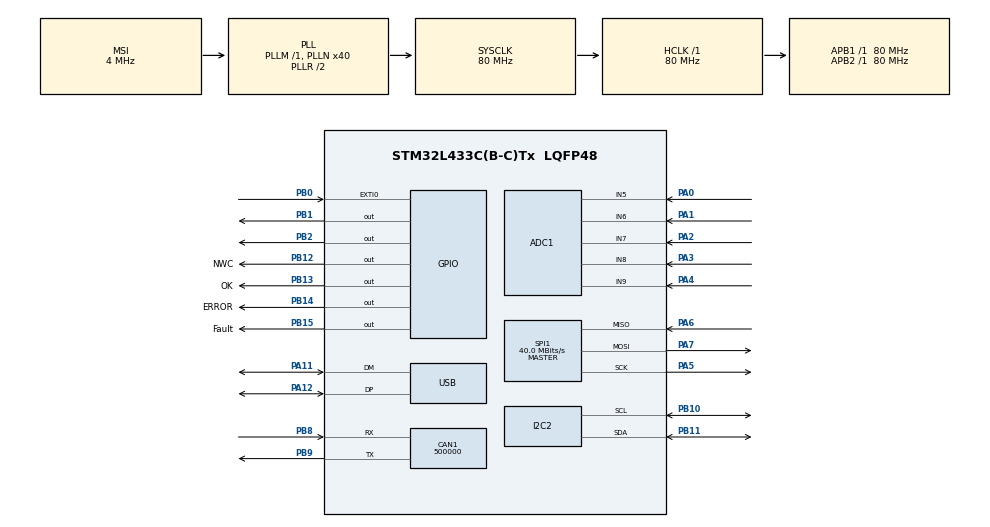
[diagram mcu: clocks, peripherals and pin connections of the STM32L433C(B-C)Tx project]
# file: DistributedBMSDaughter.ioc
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ADC1.Channel-0\#ChannelRegularConversion=ADC_CHANNEL_5
ADC1.NbrOfConversionFlag=1
ADC1.OffsetNumber-0\#ChannelRegularConversion=ADC_OFFSET_NONE
ADC1.Rank-0\#ChannelRegularConversion=1
ADC1.SamplingTime-0\#ChannelRegularConversion=ADC_SAMPLETIME_2CYCLES_5
ADC1.master=1
CAN1.BS1=CAN_BS1_3TQ
CAN1.BS2=CAN_BS2_6TQ
CAN1.CalculateBaudRate=500000
CAN1.CalculateTimeBit=2000
CAN1.CalculateTimeQuantum=200.0
I2C2.Timing=0x10D19CE4
Mcu.Family=STM32L4
Mcu.Name=STM32L433C(B-C)Tx
Mcu.Package=LQFP48
NVIC.PriorityGroup=NVIC_PRIORITYGROUP_4
PA0.Signal=ADCx_IN5
PA1.Signal=ADCx_IN6
PA11.Mode=Device
PA11.Signal=USB_DM
PA12.Mode=Device
PA12.Signal=USB_DP
PA13\ (JTMS-SWDIO).Mode=Trace_Asynchronous_SW
PA13\ (JTMS-SWDIO).Signal=SYS_JTMS-SWDIO
PA14\ (JTCK-SWCLK).Mode=Trace_Asynchronous_SW
PA14\ (JTCK-SWCLK).Signal=SYS_JTCK-SWCLK
PA2.Signal=ADCx_IN7
PA3.Signal=ADCx_IN8
PA4.Signal=ADCx_IN9
PA5.Mode=Full_Duplex_Master
PA5.Signal=SPI1_SCK
PA6.Mode=Full_Duplex_Master
PA6.Signal=SPI1_MISO
PA7.Mode=Full_Duplex_Master
PA7.Signal=SPI1_MOSI
PB0.Signal=GPXTI0
PB1.Signal=GPIO_Output
PB10.Mode=I2C
PB10.Signal=I2C2_SCL
PB11.Mode=I2C
PB11.Signal=I2C2_SDA
PB12.GPIO_Label=NWC
PB12.Signal=GPIO_Output
PB13.GPIO_Label=OK
PB13.Signal=GPIO_Output
PB14.GPIO_Label=ERROR
PB14.Signal=GPIO_Output
PB15.GPIO_Label=Fault
PB15.Signal=GPIO_Output
PB2.Signal=GPIO_Output
PB3\ (JTDO-TRACESWO).Mode=Trace_Asynchronous_SW
PB3\ (JTDO-TRACESWO).Signal=SYS_JTDO-SWO
PB8.Mode=CAN_Activate
PB8.Signal=CAN1_RX
PB9.Mode=CAN_Activate
PB9.Signal=CAN1_TX
ProjectManager.HeapSize=0x200
ProjectManager.StackSize=0x400
ProjectManager.TargetToolchain=STM32CubeIDE
RCC.ADCFreq_Value=48000000
RCC.AHBFreq_Value=80000000
RCC.APB1Freq_Value=80000000
RCC.APB1TimFreq_Value=80000000
RCC.APB2Freq_Value=80000000
RCC.APB2TimFreq_Value=80000000
RCC.CortexFreq_Value=80000000
RCC.HCLKFreq_Value=80000000
RCC.HSE_VALUE=8000000
RCC.HSI48_VALUE=48000000
RCC.HSI_VALUE=16000000
RCC.LSE_VALUE=32768
RCC.MSI_VALUE=4000000
RCC.PLLN=40
RCC.PLLSAI1N=24
RCC.SYSCLKFreq_VALUE=80000000
RCC.SYSCLKSource=RCC_SYSCLKSOURCE_PLLCLK
RCC.USBFreq_Value=48000000
RCC.VCOOutputFreq_Value=160000000
SH.ADCx_IN5.0=ADC1_IN5,IN5-Single-Ended
SH.ADCx_IN6.0=ADC1_IN6,IN6-Single-Ended
SH.ADCx_IN7.0=ADC1_IN7,IN7-Single-Ended
SH.ADCx_IN8.0=ADC1_IN8,IN8-Single-Ended
SH.ADCx_IN9.0=ADC1_IN9,IN9-Single-Ended
SPI1.CalculateBaudRate=40.0 MBits/s
SPI1.Direction=SPI_DIRECTION_2LINES
SPI1.Mode=SPI_MODE_MASTER
SPI1.VirtualType=VM_MASTER
board=custom

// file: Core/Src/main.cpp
/* USER CODE BEGIN Header */
/**
  ******************************************************************************
  * @file           : main.c
  * @brief          : Main program body
  ******************************************************************************
  * @attention
  *
  * Copyright (c) 2025 STMicroelectronics.
  * All rights reserved.
  *
  * This software is licensed under terms that can be found in the LICENSE file
  * in the root directory of this software component.
  * If no LICENSE file comes with this software, it is provided AS-IS.
  *
  ******************************************************************************
  */
/* USER CODE END Header */
#include "main.h"

/* USER CODE BEGIN Includes */
#include "BQ76920.hpp"
/* USER CODE END Includes */

ADC_HandleTypeDef hadc1;

CAN_HandleTypeDef hcan1;

I2C_HandleTypeDef hi2c2;

SPI_HandleTypeDef hspi1;

PCD_HandleTypeDef hpcd_USB_FS;

void SystemClock_Config(void);
void PeriphCommonClock_Config(void);
static void MX_GPIO_Init(void);
static void MX_ADC1_Init(void);
static void MX_CAN1_Init(void);
static void MX_I2C2_Init(void);
static void MX_SPI1_Init(void);
static void MX_USB_PCD_Init(void);

int main(void)
{

  /* MCU Configuration--------------------------------------------------------*/

  /* Reset of all peripherals, Initializes the Flash interface and the Systick. */
  HAL_Init();

  /* Configure the system clock */
  SystemClock_Config();

  /* Configure the peripherals common clocks */
  PeriphCommonClock_Config();

  /* Initialize all configured peripherals */
  MX_GPIO_Init();
  MX_ADC1_Init();
  MX_CAN1_Init();
  MX_I2C2_Init();
  MX_SPI1_Init();
  MX_USB_PCD_Init();
  /* USER CODE BEGIN 2 */

  BQ76920 bq(&hi2c2, 0x08);

  if (bq.init() != BQ76920::Error::OK) {
	  // handle init error
  }

  uint16_t cell1_mv = 0;
  if (bq.readCellVoltage(1, &cell1_mv) == BQ76920::Error::OK) {
	  // now cell1_mv holds millivolts of cell 1
  }

  uint16_t pack_mv = 0;
  bq.readPackVoltage(&pack_mv);

  /* USER CODE END 2 */

  /* Infinite loop */
  while (1)
  {

  }
}

void SystemClock_Config(void)
{
  RCC_OscInitTypeDef RCC_OscInitStruct = {0};
  RCC_ClkInitTypeDef RCC_ClkInitStruct = {0};

  /** Configure the main internal regulator output voltage
  */
  if (HAL_PWREx_ControlVoltageScaling(PWR_REGULATOR_VOLTAGE_SCALE1) != HAL_OK)
  {
    Error_Handler();
  }

  /** Initializes the RCC Oscillators according to the specified parameters
  * in the RCC_OscInitTypeDef structure.
  */
  RCC_OscInitStruct.OscillatorType = RCC_OSCILLATORTYPE_MSI;
  RCC_OscInitStruct.MSIState = RCC_MSI_ON;
  RCC_OscInitStruct.MSICalibrationValue = 0;
  RCC_OscInitStruct.MSIClockRange = RCC_MSIRANGE_6;
  RCC_OscInitStruct.PLL.PLLState = RCC_PLL_ON;
  RCC_OscInitStruct.PLL.PLLSource = RCC_PLLSOURCE_MSI;
  RCC_OscInitStruct.PLL.PLLM = 1;
  RCC_OscInitStruct.PLL.PLLN = 40;
  RCC_OscInitStruct.PLL.PLLP = RCC_PLLP_DIV7;
  RCC_OscInitStruct.PLL.PLLQ = RCC_PLLQ_DIV2;
  RCC_OscInitStruct.PLL.PLLR = RCC_PLLR_DIV2;
  if (HAL_RCC_OscConfig(&RCC_OscInitStruct) != HAL_OK)
  {
    Error_Handler();
  }

  /** Initializes the CPU, AHB and APB buses clocks
  */
  RCC_ClkInitStruct.ClockType = RCC_CLOCKTYPE_HCLK|RCC_CLOCKTYPE_SYSCLK
                              |RCC_CLOCKTYPE_PCLK1|RCC_CLOCKTYPE_PCLK2;
  RCC_ClkInitStruct.SYSCLKSource = RCC_SYSCLKSOURCE_PLLCLK;
  RCC_ClkInitStruct.AHBCLKDivider = RCC_SYSCLK_DIV1;
  RCC_ClkInitStruct.APB1CLKDivider = RCC_HCLK_DIV1;
  RCC_ClkInitStruct.APB2CLKDivider = RCC_HCLK_DIV1;

  if (HAL_RCC_ClockConfig(&RCC_ClkInitStruct, FLASH_LATENCY_4) != HAL_OK)
  {
    Error_Handler();
  }
}

void PeriphCommonClock_Config(void)
{
  RCC_PeriphCLKInitTypeDef PeriphClkInit = {0};

  /** Initializes the peripherals clock
  */
  PeriphClkInit.PeriphClockSelection = RCC_PERIPHCLK_USB|RCC_PERIPHCLK_ADC;
  PeriphClkInit.AdcClockSelection = RCC_ADCCLKSOURCE_PLLSAI1;
  PeriphClkInit.UsbClockSelection = RCC_USBCLKSOURCE_PLLSAI1;
  PeriphClkInit.PLLSAI1.PLLSAI1Source = RCC_PLLSOURCE_MSI;
  PeriphClkInit.PLLSAI1.PLLSAI1M = 1;
  PeriphClkInit.PLLSAI1.PLLSAI1N = 24;
  PeriphClkInit.PLLSAI1.PLLSAI1P = RCC_PLLP_DIV7;
  PeriphClkInit.PLLSAI1.PLLSAI1Q = RCC_PLLQ_DIV2;
  PeriphClkInit.PLLSAI1.PLLSAI1R = RCC_PLLR_DIV2;
  PeriphClkInit.PLLSAI1.PLLSAI1ClockOut = RCC_PLLSAI1_48M2CLK|RCC_PLLSAI1_ADC1CLK;
  if (HAL_RCCEx_PeriphCLKConfig(&PeriphClkInit) != HAL_OK)
  {
    Error_Handler();
  }
}

static void MX_ADC1_Init(void)
{

  ADC_ChannelConfTypeDef sConfig = {0};

  /** Common config
  */
  hadc1.Instance = ADC1;
  hadc1.Init.ClockPrescaler = ADC_CLOCK_ASYNC_DIV1;
  hadc1.Init.Resolution = ADC_RESOLUTION_12B;
  hadc1.Init.DataAlign = ADC_DATAALIGN_RIGHT;
  hadc1.Init.ScanConvMode = ADC_SCAN_DISABLE;
  hadc1.Init.EOCSelection = ADC_EOC_SINGLE_CONV;
  hadc1.Init.LowPowerAutoWait = DISABLE;
  hadc1.Init.ContinuousConvMode = DISABLE;
  hadc1.Init.NbrOfConversion = 1;
  hadc1.Init.DiscontinuousConvMode = DISABLE;
  hadc1.Init.ExternalTrigConv = ADC_SOFTWARE_START;
  hadc1.Init.ExternalTrigConvEdge = ADC_EXTERNALTRIGCONVEDGE_NONE;
  hadc1.Init.DMAContinuousRequests = DISABLE;
  hadc1.Init.Overrun = ADC_OVR_DATA_PRESERVED;
  hadc1.Init.OversamplingMode = DISABLE;
  if (HAL_ADC_Init(&hadc1) != HAL_OK)
  {
    Error_Handler();
  }

  /** Configure Regular Channel
  */
  sConfig.Channel = ADC_CHANNEL_5;
  sConfig.Rank = ADC_REGULAR_RANK_1;
  sConfig.SamplingTime = ADC_SAMPLETIME_2CYCLES_5;
  sConfig.SingleDiff = ADC_SINGLE_ENDED;
  sConfig.OffsetNumber = ADC_OFFSET_NONE;
  sConfig.Offset = 0;
  if (HAL_ADC_ConfigChannel(&hadc1, &sConfig) != HAL_OK)
  {
    Error_Handler();
  }

}

static void MX_CAN1_Init(void)
{

  hcan1.Instance = CAN1;
  hcan1.Init.Prescaler = 16;
  hcan1.Init.Mode = CAN_MODE_NORMAL;
  hcan1.Init.SyncJumpWidth = CAN_SJW_1TQ;
  hcan1.Init.TimeSeg1 = CAN_BS1_3TQ;
  hcan1.Init.TimeSeg2 = CAN_BS2_6TQ;
  hcan1.Init.TimeTriggeredMode = DISABLE;
  hcan1.Init.AutoBusOff = DISABLE;
  hcan1.Init.AutoWakeUp = DISABLE;
  hcan1.Init.AutoRetransmission = DISABLE;
  hcan1.Init.ReceiveFifoLocked = DISABLE;
  hcan1.Init.TransmitFifoPriority = DISABLE;
  if (HAL_CAN_Init(&hcan1) != HAL_OK)
  {
    Error_Handler();
  }

}

static void MX_I2C2_Init(void)
{

  hi2c2.Instance = I2C2;
  hi2c2.Init.Timing = 0x10D19CE4;
  hi2c2.Init.OwnAddress1 = 0;
  hi2c2.Init.AddressingMode = I2C_ADDRESSINGMODE_7BIT;
  hi2c2.Init.DualAddressMode = I2C_DUALADDRESS_DISABLE;
  hi2c2.Init.OwnAddress2 = 0;
  hi2c2.Init.OwnAddress2Masks = I2C_OA2_NOMASK;
  hi2c2.Init.GeneralCallMode = I2C_GENERALCALL_DISABLE;
  hi2c2.Init.NoStretchMode = I2C_NOSTRETCH_DISABLE;
  if (HAL_I2C_Init(&hi2c2) != HAL_OK)
  {
    Error_Handler();
  }

  /** Configure Analogue filter
  */
  if (HAL_I2CEx_ConfigAnalogFilter(&hi2c2, I2C_ANALOGFILTER_ENABLE) != HAL_OK)
  {
    Error_Handler();
  }

  /** Configure Digital filter
  */
  if (HAL_I2CEx_ConfigDigitalFilter(&hi2c2, 0) != HAL_OK)
  {
    Error_Handler();
  }

}

static void MX_SPI1_Init(void)
{

  /* SPI1 parameter configuration*/
  hspi1.Instance = SPI1;
  hspi1.Init.Mode = SPI_MODE_MASTER;
  hspi1.Init.Direction = SPI_DIRECTION_2LINES;
  hspi1.Init.DataSize = SPI_DATASIZE_4BIT;
  hspi1.Init.CLKPolarity = SPI_POLARITY_LOW;
  hspi1.Init.CLKPhase = SPI_PHASE_1EDGE;
  hspi1.Init.NSS = SPI_NSS_SOFT;
  hspi1.Init.BaudRatePrescaler = SPI_BAUDRATEPRESCALER_2;
  hspi1.Init.FirstBit = SPI_FIRSTBIT_MSB;
  hspi1.Init.TIMode = SPI_TIMODE_DISABLE;
  hspi1.Init.CRCCalculation = SPI_CRCCALCULATION_DISABLE;
  hspi1.Init.CRCPolynomial = 7;
  hspi1.Init.CRCLength = SPI_CRC_LENGTH_DATASIZE;
  hspi1.Init.NSSPMode = SPI_NSS_PULSE_ENABLE;
  if (HAL_SPI_Init(&hspi1) != HAL_OK)
  {
    Error_Handler();
  }

}

static void MX_USB_PCD_Init(void)
{

  hpcd_USB_FS.Instance = USB;
  hpcd_USB_FS.Init.dev_endpoints = 8;
  hpcd_USB_FS.Init.speed = PCD_SPEED_FULL;
  hpcd_USB_FS.Init.phy_itface = PCD_PHY_EMBEDDED;
  hpcd_USB_FS.Init.Sof_enable = DISABLE;
  hpcd_USB_FS.Init.low_power_enable = DISABLE;
  hpcd_USB_FS.Init.lpm_enable = DISABLE;
  hpcd_USB_FS.Init.battery_charging_enable = DISABLE;
  if (HAL_PCD_Init(&hpcd_USB_FS) != HAL_OK)
  {
    Error_Handler();
  }

}

static void MX_GPIO_Init(void)
{
  GPIO_InitTypeDef GPIO_InitStruct = {0};

  /* GPIO Ports Clock Enable */
  __HAL_RCC_GPIOA_CLK_ENABLE();
  __HAL_RCC_GPIOB_CLK_ENABLE();

  /*Configure GPIO pin Output Level */
  HAL_GPIO_WritePin(GPIOB, GPIO_PIN_1|GPIO_PIN_2|NWC_Pin|OK_Pin
                          |ERROR_Pin|Fault_Pin, GPIO_PIN_RESET);

  /*Configure GPIO pin : PB0 */
  GPIO_InitStruct.Pin = GPIO_PIN_0;
  GPIO_InitStruct.Mode = GPIO_MODE_IT_RISING;
  GPIO_InitStruct.Pull = GPIO_NOPULL;
  HAL_GPIO_Init(GPIOB, &GPIO_InitStruct);

  /*Configure GPIO pins : PB1 PB2 NWC_Pin OK_Pin
                           ERROR_Pin Fault_Pin */
  GPIO_InitStruct.Pin = GPIO_PIN_1|GPIO_PIN_2|NWC_Pin|OK_Pin
                          |ERROR_Pin|Fault_Pin;
  GPIO_InitStruct.Mode = GPIO_MODE_OUTPUT_PP;
  GPIO_InitStruct.Pull = GPIO_NOPULL;
  GPIO_InitStruct.Speed = GPIO_SPEED_FREQ_LOW;
  HAL_GPIO_Init(GPIOB, &GPIO_InitStruct);

}

void Error_Handler(void)
{
  __disable_irq();
  while (1)
  {
  }
}
